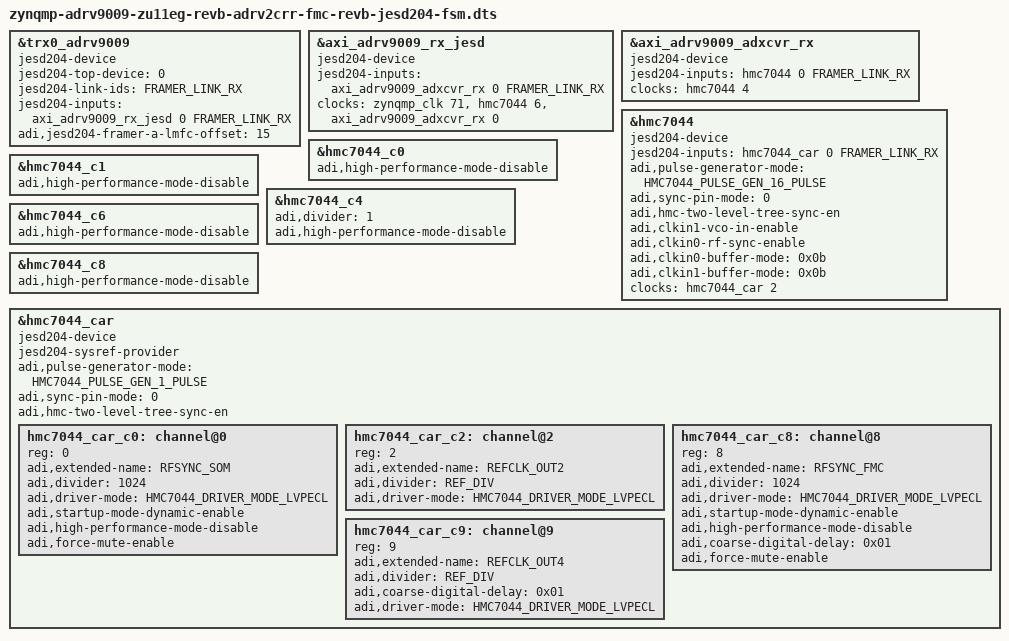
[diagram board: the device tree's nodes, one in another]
// SPDX-License-Identifier: GPL-2.0
/*
 * ADRV2CRR-FMC using ADRV9009-ZU11EG Rev.B System on Module
 *
 * https://wiki.analog.com/resources/eval/user-guides/adrv9009
 * https://wiki.analog.com/resources/tools-software/linux-drivers/iio-transceiver/adrv9009
 * https://wiki.analog.com/resources/tools-software/linux-software/adrv9009_advanced_plugin
 * https://wiki.analog.com/resources/eval/user-guides/adrv9009-zu11eg/adrv2crr-fmc_carrier_board
 *
 * hdl_project: <adrv9009zu11eg/adrv2crr_fmc>
 * board_revision: <B>
 *
 * Copyright (C) 2019 Analog Devices Inc.
 */

#include "zynqmp-adrv9009-zu11eg-revb-adrv2crr-fmc-revb.dts"
#include <dt-bindings/iio/frequency/hmc7044.h>
#include <dt-bindings/iio/adc/adi,adrv9009.h>

&trx0_adrv9009 {
	jesd204-device;
	#jesd204-cells = <2>;
	jesd204-top-device = <0>; /* This is the TOP device */
	jesd204-link-ids = <FRAMER_LINK_RX>;

	jesd204-inputs =
		<&axi_adrv9009_rx_jesd 0 FRAMER_LINK_RX>;

	/delete-property/ interrupts;
	adi,jesd204-framer-a-lmfc-offset = <15>;
};

// &trx1_adrv9009 {
// 	jesd204-device;
// 	#jesd204-cells = <2>;
// 	jesd204-inputs =
//                 <&axi_adrv9009_rx_jesd 0 FRAMER_LINK_RX>,
// 		<&axi_adrv9009_rx_os_jesd 0 FRAMER_LINK_ORX>,
// 		<&axi_adrv9009_core_tx 0 DEFRAMER_LINK_TX>;

// 	/delete-property/ interrupts;
// 	adi,jesd204-framer-a-lmfc-offset = <15>;
// };

// &axi_adrv9009_core_tx {
// 	jesd204-device;
// 	#jesd204-cells = <2>;
// 	jesd204-inputs = <&axi_adrv9009_tx_jesd 0 DEFRAMER_LINK_TX>;
// };

&axi_adrv9009_rx_jesd {
	jesd204-device;
	#jesd204-cells = <2>;
	jesd204-inputs = <&axi_adrv9009_adxcvr_rx 0 FRAMER_LINK_RX>;
	clocks = <&zynqmp_clk 71>, <&hmc7044 6>, <&axi_adrv9009_adxcvr_rx 0>;
	clock-names = "s_axi_aclk", "device_clk", "lane_clk";
};

// &axi_adrv9009_rx_os_jesd {
// 	jesd204-device;
// 	#jesd204-cells = <2>;
// 	jesd204-inputs = <&axi_adrv9009_adxcvr_rx_os 0 FRAMER_LINK_ORX>;
// 	clocks = <&zynqmp_clk 71>, <&hmc7044 6>, <&axi_adrv9009_adxcvr_rx_os 0>;
// 	clock-names = "s_axi_aclk", "device_clk", "lane_clk";
// };

// &axi_adrv9009_tx_jesd {
// 	jesd204-device;
// 	#jesd204-cells = <2>;
// 	jesd204-inputs = <&axi_adrv9009_adxcvr_tx 0 DEFRAMER_LINK_TX>;
// 	clocks = <&zynqmp_clk 71>, <&hmc7044 6>, <&axi_adrv9009_adxcvr_tx 0>;
// 	clock-names = "s_axi_aclk", "device_clk", "lane_clk";
// };

&axi_adrv9009_adxcvr_rx {
	jesd204-device;
	#jesd204-cells = <2>;
	jesd204-inputs =  <&hmc7044 0 FRAMER_LINK_RX>;
	clock-names = "conv";
	clocks = <&hmc7044 4>;
};

// &axi_adrv9009_adxcvr_rx_os {
// 	jesd204-device;
// 	#jesd204-cells = <2>;
// 	jesd204-inputs =  <&hmc7044 0 FRAMER_LINK_ORX>;
// 	clock-names = "conv";
// 	clocks = <&hmc7044 4>;
// };

// &axi_adrv9009_adxcvr_tx {
// 	jesd204-device;
// 	#jesd204-cells = <2>;
// 	jesd204-inputs =  <&hmc7044 0 DEFRAMER_LINK_TX>;
// 	clock-names = "conv";
// 	clocks = <&hmc7044 4>;
// };

&hmc7044 {
	jesd204-device;
	#jesd204-cells = <2>;
	jesd204-inputs = <&hmc7044_car 0 FRAMER_LINK_RX>;

	adi,pulse-generator-mode = <HMC7044_PULSE_GEN_16_PULSE>;
	adi,sync-pin-mode = <0>;

	/delete-property/ adi,pll2-autocal-bypass-manual-cap-bank-sel;
	adi,hmc-two-level-tree-sync-en;

	adi,clkin1-vco-in-enable;
	adi,clkin0-rf-sync-enable;

	adi,clkin0-buffer-mode = <0x0b>; /* Needs HW modification - remove AC couble Caps */
	adi,clkin1-buffer-mode = <0x0b>;

	clocks = <&hmc7044_car 2>;
	clock-names = "clkin1";
};

&hmc7044_c0 {
	adi,high-performance-mode-disable;
};

&hmc7044_c1 {
	adi,high-performance-mode-disable;
};

&hmc7044_c4 {
	adi,divider = <1>;
	adi,high-performance-mode-disable;
};

&hmc7044_c6 {
	adi,high-performance-mode-disable;
};

&hmc7044_c8 {
	adi,high-performance-mode-disable;
};

#define REF_DIV 12 /* 2949.12 / 245.76 MHz */

&hmc7044_car {
	jesd204-device;
	#jesd204-cells = <2>;
	jesd204-sysref-provider;

	/* SYSREF Provider */
	adi,pulse-generator-mode = <HMC7044_PULSE_GEN_1_PULSE>;
	adi,sync-pin-mode = <0>;

	/delete-property/ adi,pll2-autocal-bypass-manual-cap-bank-sel;
	adi,hmc-two-level-tree-sync-en;

	hmc7044_car_c0: channel@0 {
		reg = <0>;
		adi,extended-name = "RFSYNC_SOM";
		adi,divider = <1024>; /* set by the jesd204-fsm */
		adi,driver-mode = <HMC7044_DRIVER_MODE_LVPECL>;
		adi,startup-mode-dynamic-enable;
		adi,high-performance-mode-disable;
		adi,force-mute-enable;
	};

	hmc7044_car_c2: channel@2 {
		reg = <2>;
		adi,extended-name = "REFCLK_OUT2";
		adi,divider = <REF_DIV>;
		adi,driver-mode = <HMC7044_DRIVER_MODE_LVPECL>;
	};

	hmc7044_car_c8: channel@8 {
		reg = <8>;
		adi,extended-name = "RFSYNC_FMC";
		adi,divider = <1024>; /* set by the jesd204-fsm */
		adi,driver-mode = <HMC7044_DRIVER_MODE_LVPECL>;
		adi,startup-mode-dynamic-enable;
		adi,high-performance-mode-disable;
		adi,coarse-digital-delay = <0x01>;
		adi,force-mute-enable;
	};

	hmc7044_car_c9: channel@9 {
		reg = <9>;
		adi,extended-name = "REFCLK_OUT4";
		adi,divider = <REF_DIV>;
		adi,coarse-digital-delay = <0x01>;
		adi,driver-mode = <HMC7044_DRIVER_MODE_LVPECL>;
	};
};
